AUTOSAR XML (schema 4-0-3)
package /ComponentTypes
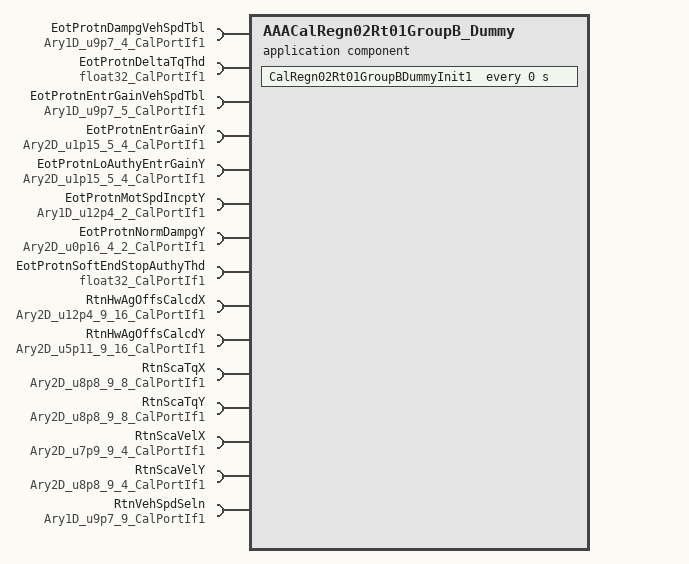
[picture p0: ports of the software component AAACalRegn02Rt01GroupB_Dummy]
  application sw component type AAACalRegn02Rt01GroupB_Dummy
    15 x require port:
      EotProtnDampgVehSpdTbl: parameter-require-com-spec{init-value=[0, 640, 1280, 2560], parameter=Ary1D}, required-interface=Ary1D_u9p7_4_CalPortIf1
      EotProtnDeltaTqThd: parameter-require-com-spec{init-value=0, parameter=Val}, required-interface=float32_CalPortIf1
      EotProtnEntrGainVehSpdTbl: parameter-require-com-spec{init-value=[0, 640, 1280, 1920, 2560], parameter=Ary1D}, required-interface=Ary1D_u9p7_5_CalPortIf1
      EotProtnEntrGainY: parameter-require-com-spec{init-value=5 x [0, 10813, 21627, 32768], parameter=Ary2D}, required-interface=Ary2D_u1p15_5_4_CalPortIf1
      EotProtnLoAuthyEntrGainY: parameter-require-com-spec{init-value=5 x [0, 9830, 22938, 32768], parameter=Ary2D}, required-interface=Ary2D_u1p15_5_4_CalPortIf1
      EotProtnMotSpdIncptY: parameter-require-com-spec{init-value=[10400, 10400], parameter=Ary1D}, required-interface=Ary1D_u12p4_2_CalPortIf1
      EotProtnNormDampgY: parameter-require-com-spec{init-value=[[0, 262], [0, 262], [0, 262], [0, 262]], parameter=Ary2D}, required-interface=Ary2D_u0p16_4_2_CalPortIf1
      EotProtnSoftEndStopAuthyThd: parameter-require-com-spec{init-value=0.9, parameter=Val}, required-interface=float32_CalPortIf1
      RtnHwAgOffsCalcdX: parameter-require-com-spec{init-value=9 x [0, 8, 16, 80, 160, 320, 480, 720, 960, 1440, 1920, 2880, 4320, 5760, 7200, 8640], parameter=Ary2D}, required-interface=Ary2D_u12p4_9_16_CalPortIf1
      RtnHwAgOffsCalcdY: parameter-require-com-spec{init-value=9 x 16 x 0, parameter=Ary2D}, required-interface=Ary2D_u5p11_9_16_CalPortIf1
      RtnScaTqX: parameter-require-com-spec{init-value=9 x [0, 128, 256, 512, 768, 1024, 1280, 2560], parameter=Ary2D}, required-interface=Ary2D_u8p8_9_8_CalPortIf1
      RtnScaTqY: parameter-require-com-spec{init-value=9 x 8 x 256, parameter=Ary2D}, required-interface=Ary2D_u8p8_9_8_CalPortIf1
      RtnScaVelX: parameter-require-com-spec{init-value=9 x [0, 20480, 21504, 21504], parameter=Ary2D}, required-interface=Ary2D_u7p9_9_4_CalPortIf1
      RtnScaVelY: parameter-require-com-spec{init-value=9 x [256, 256, 256, 256], parameter=Ary2D}, required-interface=Ary2D_u8p8_9_4_CalPortIf1
      RtnVehSpdSeln: parameter-require-com-spec{init-value=[0, 384, 896, 1536, 2560, 3840, 5760, 7680, 10240], parameter=Ary1D}, required-interface=Ary1D_u9p7_9_CalPortIf1
    behavior AAACalRegn02Rt01GroupB_Dummy_InternalBehavior: supports-multiple-instantiation=true
      timing event AAACalRegn02Rt01GroupB_Dummy_InitEvent: start-on-event=CalRegn02Rt01GroupBDummyInit1, period=0
      runnable CalRegn02Rt01GroupBDummyInit1
  swc implementation AAACalRegn02Rt00GroupB_Dummy_Implementation: behavior=AAACalRegn02Rt01GroupB_Dummy_InternalBehavior
    code-descriptors:
      code Default: artifact-descriptors=autosar-engineering-object={short-label=Default, category=SWSRC}
